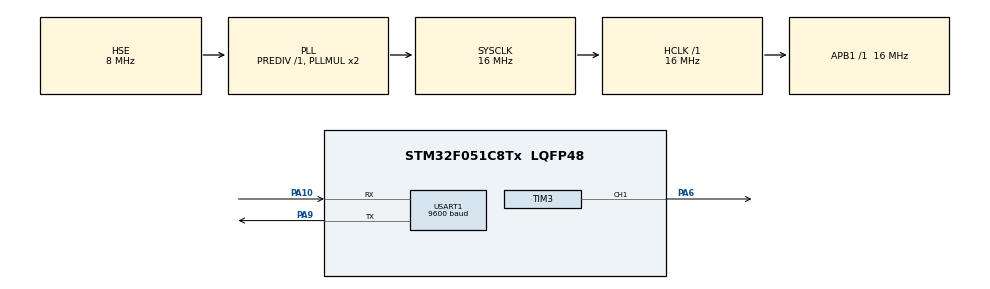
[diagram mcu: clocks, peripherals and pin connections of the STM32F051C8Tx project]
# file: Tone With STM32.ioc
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Mcu.Family=STM32F0
Mcu.Name=STM32F051C8Tx
Mcu.Package=LQFP48
NVIC.USART1_IRQn=true\:0\:0\:false\:false\:true\:true\:true
PA10.Mode=Asynchronous
PA10.Signal=USART1_RX
PA13.Mode=Serial_Wire
PA13.Signal=SYS_SWDIO
PA14.Mode=Serial_Wire
PA14.Signal=SYS_SWCLK
PA6.Signal=S_TIM3_CH1
PA9.Mode=Asynchronous
PA9.Signal=USART1_TX
PF0-OSC_IN.Mode=HSE-External-Oscillator
PF0-OSC_IN.Signal=RCC_OSC_IN
PF1-OSC_OUT.Mode=HSE-External-Oscillator
PF1-OSC_OUT.Signal=RCC_OSC_OUT
ProjectManager.HeapSize=0x200
ProjectManager.StackSize=0x400
ProjectManager.TargetToolchain=STM32CubeIDE
RCC.AHBFreq_Value=16000000
RCC.APB1Freq_Value=16000000
RCC.APB1TimFreq_Value=16000000
RCC.EnbaleCSS=true
RCC.HCLKFreq_Value=16000000
RCC.PLLSourceVirtual=RCC_PLLSOURCE_HSE
RCC.RTCClockSelection=RCC_RTCCLKSOURCE_LSE
RCC.SYSCLKFreq_VALUE=16000000
RCC.SYSCLKSource=RCC_SYSCLKSOURCE_PLLCLK
SH.S_TIM3_CH1.0=TIM3_CH1,PWM Generation1 CH1
TIM3.Channel-PWM\ Generation1\ CH1=TIM_CHANNEL_1
TIM3.Period=0xff
TIM3.Prescaler=16000000/(256*2000)
USART1.BaudRate=9600
USART1.VirtualMode-Asynchronous=VM_ASYNC
VP_TIM15_VS_ClockSourceINT.Mode=Internal
VP_TIM3_VS_ClockSourceINT.Mode=Internal
board=custom

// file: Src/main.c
/* USER CODE BEGIN Header */
/**
 ******************************************************************************
 * @file           : main.c
 * @brief          : Main program body
 ******************************************************************************
 * @attention
 *
 * <h2><center>&copy; Copyright (c) 2019 STMicroelectronics.
 * All rights reserved.</center></h2>
 *
 * This software component is licensed by ST under BSD 3-Clause license,
 * the "License"; You may not use this file except in compliance with the
 * License. You may obtain a copy of the License at:
 *                        opensource.org/licenses/BSD-3-Clause
 *
 ******************************************************************************
 */
/* USER CODE END Header */
#include "main.h"

/* USER CODE BEGIN Includes */
#include "Melody.h"

/* USER CODE END Includes */

TIM_HandleTypeDef htim3;
TIM_HandleTypeDef htim15;

UART_HandleTypeDef huart1;

/* USER CODE BEGIN PV */
uint8_t get_data;
extern const Melody_Typedef OK_Melody;
extern const Melody_Typedef ERROR_Melody;
const Melody_Typedef TOUCH1_Melody = {
		/*notes*/	{NOTE_GS6},
		/*tempo*/	{6},
		/*Count*/	1
};

/* USER CODE END PV */

void SystemClock_Config(void);
static void MX_GPIO_Init(void);
static void MX_TIM3_Init(void);
static void MX_TIM15_Init(void);
static void MX_USART1_UART_Init(void);

int main(void)
{

	/* MCU Configuration--------------------------------------------------------*/

	/* Reset of all peripherals, Initializes the Flash interface and the Systick. */
	HAL_Init();

	/* Configure the system clock */
	SystemClock_Config();

	/* Initialize all configured peripherals */
	MX_GPIO_Init();
	MX_TIM3_Init();
	MX_TIM15_Init();
	MX_USART1_UART_Init();
	/* USER CODE BEGIN 2 */
	HAL_TIM_Base_Start_IT(&htim15);
	HAL_UART_Receive_IT(&huart1,&get_data ,1);
	HAL_TIM_PWM_Start(&htim3,TIM_CHANNEL_1);

	/* USER CODE END 2 */

	/* Infinite loop */
	/* USER CODE BEGIN WHILE */
	HAL_Delay(500);

	while (1)
	{

		Play_Melody(TOUCH1_Melody ,5);

		HAL_Delay(500);

		Play_Melody(OK_Melody ,5);

		HAL_Delay(500);

		Play_Melody(ERROR_Melody ,5);

		HAL_Delay(500);

		/* USER CODE END WHILE */

	}
}

void SystemClock_Config(void)
{
	RCC_OscInitTypeDef RCC_OscInitStruct = {0};
	RCC_ClkInitTypeDef RCC_ClkInitStruct = {0};
	RCC_PeriphCLKInitTypeDef PeriphClkInit = {0};

	/** Initializes the RCC Oscillators according to the specified parameters
	 * in the RCC_OscInitTypeDef structure.
	 */
	RCC_OscInitStruct.OscillatorType = RCC_OSCILLATORTYPE_HSE;
	RCC_OscInitStruct.HSEState = RCC_HSE_ON;
	RCC_OscInitStruct.PLL.PLLState = RCC_PLL_ON;
	RCC_OscInitStruct.PLL.PLLSource = RCC_PLLSOURCE_HSE;
	RCC_OscInitStruct.PLL.PLLMUL = RCC_PLL_MUL2;
	RCC_OscInitStruct.PLL.PREDIV = RCC_PREDIV_DIV1;
	if (HAL_RCC_OscConfig(&RCC_OscInitStruct) != HAL_OK)
	{
		Error_Handler();
	}
	/** Initializes the CPU, AHB and APB buses clocks
	 */
	RCC_ClkInitStruct.ClockType = RCC_CLOCKTYPE_HCLK|RCC_CLOCKTYPE_SYSCLK
			|RCC_CLOCKTYPE_PCLK1;
	RCC_ClkInitStruct.SYSCLKSource = RCC_SYSCLKSOURCE_PLLCLK;
	RCC_ClkInitStruct.AHBCLKDivider = RCC_SYSCLK_DIV1;
	RCC_ClkInitStruct.APB1CLKDivider = RCC_HCLK_DIV1;

	if (HAL_RCC_ClockConfig(&RCC_ClkInitStruct, FLASH_LATENCY_0) != HAL_OK)
	{
		Error_Handler();
	}
	PeriphClkInit.PeriphClockSelection = RCC_PERIPHCLK_USART1;
	PeriphClkInit.Usart1ClockSelection = RCC_USART1CLKSOURCE_PCLK1;
	if (HAL_RCCEx_PeriphCLKConfig(&PeriphClkInit) != HAL_OK)
	{
		Error_Handler();
	}
	/** Enables the Clock Security System
	 */
	HAL_RCC_EnableCSS();
}

static void MX_TIM3_Init(void)
{

	TIM_ClockConfigTypeDef sClockSourceConfig = {0};
	TIM_MasterConfigTypeDef sMasterConfig = {0};
	TIM_OC_InitTypeDef sConfigOC = {0};

	htim3.Instance = TIM3;
	htim3.Init.Prescaler = 16000000/(256*2000);
	htim3.Init.CounterMode = TIM_COUNTERMODE_UP;
	htim3.Init.Period = 0xff;
	htim3.Init.ClockDivision = TIM_CLOCKDIVISION_DIV1;
	htim3.Init.AutoReloadPreload = TIM_AUTORELOAD_PRELOAD_DISABLE;
	if (HAL_TIM_Base_Init(&htim3) != HAL_OK)
	{
		Error_Handler();
	}
	sClockSourceConfig.ClockSource = TIM_CLOCKSOURCE_INTERNAL;
	if (HAL_TIM_ConfigClockSource(&htim3, &sClockSourceConfig) != HAL_OK)
	{
		Error_Handler();
	}
	if (HAL_TIM_PWM_Init(&htim3) != HAL_OK)
	{
		Error_Handler();
	}
	sMasterConfig.MasterOutputTrigger = TIM_TRGO_RESET;
	sMasterConfig.MasterSlaveMode = TIM_MASTERSLAVEMODE_DISABLE;
	if (HAL_TIMEx_MasterConfigSynchronization(&htim3, &sMasterConfig) != HAL_OK)
	{
		Error_Handler();
	}
	sConfigOC.OCMode = TIM_OCMODE_PWM1;
	sConfigOC.Pulse = 0;
	sConfigOC.OCPolarity = TIM_OCPOLARITY_HIGH;
	sConfigOC.OCFastMode = TIM_OCFAST_DISABLE;
	if (HAL_TIM_PWM_ConfigChannel(&htim3, &sConfigOC, TIM_CHANNEL_1) != HAL_OK)
	{
		Error_Handler();
	}
	HAL_TIM_MspPostInit(&htim3);

}

static void MX_TIM15_Init(void)
{

	TIM_ClockConfigTypeDef sClockSourceConfig = {0};
	TIM_MasterConfigTypeDef sMasterConfig = {0};

	htim15.Instance = TIM15;
	htim15.Init.Prescaler = 0;
	htim15.Init.CounterMode = TIM_COUNTERMODE_UP;
	htim15.Init.Period = 65535;
	htim15.Init.ClockDivision = TIM_CLOCKDIVISION_DIV1;
	htim15.Init.RepetitionCounter = 0;
	htim15.Init.AutoReloadPreload = TIM_AUTORELOAD_PRELOAD_DISABLE;
	if (HAL_TIM_Base_Init(&htim15) != HAL_OK)
	{
		Error_Handler();
	}
	sClockSourceConfig.ClockSource = TIM_CLOCKSOURCE_INTERNAL;
	if (HAL_TIM_ConfigClockSource(&htim15, &sClockSourceConfig) != HAL_OK)
	{
		Error_Handler();
	}
	sMasterConfig.MasterOutputTrigger = TIM_TRGO_RESET;
	sMasterConfig.MasterSlaveMode = TIM_MASTERSLAVEMODE_DISABLE;
	if (HAL_TIMEx_MasterConfigSynchronization(&htim15, &sMasterConfig) != HAL_OK)
	{
		Error_Handler();
	}

}

static void MX_USART1_UART_Init(void)
{

	huart1.Instance = USART1;
	huart1.Init.BaudRate = 9600;
	huart1.Init.WordLength = UART_WORDLENGTH_8B;
	huart1.Init.StopBits = UART_STOPBITS_1;
	huart1.Init.Parity = UART_PARITY_NONE;
	huart1.Init.Mode = UART_MODE_TX_RX;
	huart1.Init.HwFlowCtl = UART_HWCONTROL_NONE;
	huart1.Init.OverSampling = UART_OVERSAMPLING_16;
	huart1.Init.OneBitSampling = UART_ONE_BIT_SAMPLE_DISABLE;
	huart1.AdvancedInit.AdvFeatureInit = UART_ADVFEATURE_NO_INIT;
	if (HAL_UART_Init(&huart1) != HAL_OK)
	{
		Error_Handler();
	}

}

static void MX_GPIO_Init(void)
{

	/* GPIO Ports Clock Enable */
	__HAL_RCC_GPIOF_CLK_ENABLE();
	__HAL_RCC_GPIOA_CLK_ENABLE();

}

void Error_Handler(void)
{
}

/************************ (C) COPYRIGHT STMicroelectronics *****END OF FILE****/
